AUTOSAR XML (schema 4-0-3)
standard types defined: UInt32, UInt8
package /AUTOSAR_Platform/DataConstrs
  range DC_UInt8: raw 0..255
package /PATAC/Facility/DataTypes/Implementation
  unit NoUnit: factor-si-to-unit=1, offset-si-to-unit=0
package /PATAC/MSM/ComponentTypes
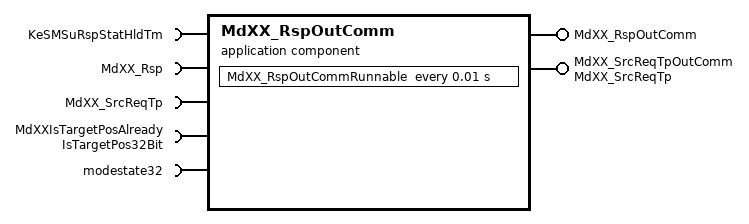
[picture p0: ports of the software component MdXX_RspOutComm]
  application sw component type MdXX_RspOutComm
    provide port MdXX_RspOutComm: provided-interface=MdXX_RspOutComm
      provided-com-specs:
        data-element=Md1_RspOutComm, init-value=0
        data-element=Md{10..19}_RspOutComm, init-value=0
        data-element=Md2_RspOutComm, init-value=0
        data-element=Md{20..29}_RspOutComm, init-value=0
        data-element=Md3_RspOutComm, init-value=0
        data-element=Md{30..32}_RspOutComm, init-value=0
        data-element=Md{4..9}_RspOutComm, init-value=0
    provide port MdXX_SrcReqTpOutComm: provided-interface=MdXX_SrcReqTp
      provided-com-specs:
        data-element=Md1_SrcTp, init-value=0
        data-element=Md{10..19}_SrcTp, init-value=0
        data-element=Md2_SrcTp, init-value=0
        data-element=Md{20..29}_SrcTp, init-value=0
        data-element=Md3_SrcTp, init-value=0
        data-element=Md{30..32}_SrcTp, init-value=0
        data-element=Md{4..9}_SrcTp, init-value=0
    5 x require port:
      KeSMSuRspStatHldTm: parameter-require-com-spec{init-value=100, parameter=Val}, required-interface=KeSMSuRspStatHldTm
      MdXX_Rsp: required-interface=MdXX_Rsp
        required-com-specs:
          data-element=Md1_Rsp, filter=data-filter-type=ALWAYS, init-value=0
          data-element=Md{10..19}_Rsp, filter=data-filter-type=ALWAYS, init-value=0
          data-element=Md2_Rsp, filter=data-filter-type=ALWAYS, init-value=0
          data-element=Md{20..29}_Rsp, filter=data-filter-type=ALWAYS, init-value=0
          data-element=Md3_Rsp, filter=data-filter-type=ALWAYS, init-value=0
          data-element=Md{30..32}_Rsp, filter=data-filter-type=ALWAYS, init-value=0
          data-element=Md{4..9}_Rsp, filter=data-filter-type=ALWAYS, init-value=0
      MdXX_SrcReqTp: required-interface=MdXX_SrcReqTp
        required-com-specs:
          data-element=Md1_SrcTp, filter=data-filter-type=ALWAYS, init-value=0
          data-element=Md{10..19}_SrcTp, filter=data-filter-type=ALWAYS, init-value=0
          data-element=Md2_SrcTp, filter=data-filter-type=ALWAYS, init-value=0
          data-element=Md{20..29}_SrcTp, filter=data-filter-type=ALWAYS, init-value=0
          data-element=Md3_SrcTp, filter=data-filter-type=ALWAYS, init-value=0
          data-element=Md{30..32}_SrcTp, filter=data-filter-type=ALWAYS, init-value=0
          data-element=Md{4..9}_SrcTp, filter=data-filter-type=ALWAYS, init-value=0
      MdXXIsTargetPosAlready: nonqueued-receiver-com-spec{data-element=IsTargetPos32Bit/Val, filter=data-filter-type=ALWAYS, init-value=0}, required-interface=IsTargetPos32Bit
      modestate32: nonqueued-receiver-com-spec{data-element=modestate32/Val, filter=data-filter-type=ALWAYS}, required-interface=modestate32
    behavior MdXX_RspOutComm_InternalBehavior
      timing event TMT_Runnable: start-on-event=MdXX_RspOutCommRunnable, period=0.01
      runnable MdXX_RspOutCommRunnable
        data-receive-point-by-arguments:
          66 x access:
            REC_IsTargetPos32Bit_Val: accessed-variable=MdXXIsTargetPosAlready.Val
            REC_MdXX_Rsp_Md1_Rsp: accessed-variable=MdXX_Rsp.Md1_Rsp
            REC_MdXX_Rsp_Md{10..19}_Rsp: accessed-variable=MdXX_Rsp.Md{10..19}_Rsp
            REC_MdXX_Rsp_Md2_Rsp: accessed-variable=MdXX_Rsp.Md2_Rsp
            REC_MdXX_Rsp_Md{20..29}_Rsp: accessed-variable=MdXX_Rsp.Md{20..29}_Rsp
            REC_MdXX_Rsp_Md3_Rsp: accessed-variable=MdXX_Rsp.Md3_Rsp
            REC_MdXX_Rsp_Md{30..32}_Rsp: accessed-variable=MdXX_Rsp.Md{30..32}_Rsp
            REC_MdXX_Rsp_Md{4..9}_Rsp: accessed-variable=MdXX_Rsp.Md{4..9}_Rsp
            REC_MdXX_SrcReqTp_Md1_SrcTp: accessed-variable=MdXX_SrcReqTp.Md1_SrcTp
            REC_MdXX_SrcReqTp_Md{10..19}_SrcTp: accessed-variable=MdXX_SrcReqTp.Md{10..19}_SrcTp
            REC_MdXX_SrcReqTp_Md2_SrcTp: accessed-variable=MdXX_SrcReqTp.Md2_SrcTp
            REC_MdXX_SrcReqTp_Md{20..29}_SrcTp: accessed-variable=MdXX_SrcReqTp.Md{20..29}_SrcTp
            REC_MdXX_SrcReqTp_Md3_SrcTp: accessed-variable=MdXX_SrcReqTp.Md3_SrcTp
            REC_MdXX_SrcReqTp_Md{30..32}_SrcTp: accessed-variable=MdXX_SrcReqTp.Md{30..32}_SrcTp
            REC_MdXX_SrcReqTp_Md{4..9}_SrcTp: accessed-variable=MdXX_SrcReqTp.Md{4..9}_SrcTp
            REC_modestate32_Val: accessed-variable=modestate32.Val
        data-send-points:
          64 x access:
            SEND_MdXX_RspOutComm_Md1_RspOutComm: accessed-variable=MdXX_RspOutComm.Md1_RspOutComm
            SEND_MdXX_RspOutComm_Md{10..19}_RspOutComm: accessed-variable=MdXX_RspOutComm.Md{10..19}_RspOutComm
            SEND_MdXX_RspOutComm_Md2_RspOutComm: accessed-variable=MdXX_RspOutComm.Md2_RspOutComm
            SEND_MdXX_RspOutComm_Md{20..29}_RspOutComm: accessed-variable=MdXX_RspOutComm.Md{20..29}_RspOutComm
            SEND_MdXX_RspOutComm_Md3_RspOutComm: accessed-variable=MdXX_RspOutComm.Md3_RspOutComm
            SEND_MdXX_RspOutComm_Md{30..32}_RspOutComm: accessed-variable=MdXX_RspOutComm.Md{30..32}_RspOutComm
            SEND_MdXX_RspOutComm_Md{4..9}_RspOutComm: accessed-variable=MdXX_RspOutComm.Md{4..9}_RspOutComm
            SEND_MdXX_SrcReqTpOutComm_Md1_SrcTp: accessed-variable=MdXX_SrcReqTpOutComm.Md1_SrcTp
            SEND_MdXX_SrcReqTpOutComm_Md{10..19}_SrcTp: accessed-variable=MdXX_SrcReqTpOutComm.Md{10..19}_SrcTp
            SEND_MdXX_SrcReqTpOutComm_Md2_SrcTp: accessed-variable=MdXX_SrcReqTpOutComm.Md2_SrcTp
            SEND_MdXX_SrcReqTpOutComm_Md{20..29}_SrcTp: accessed-variable=MdXX_SrcReqTpOutComm.Md{20..29}_SrcTp
            SEND_MdXX_SrcReqTpOutComm_Md3_SrcTp: accessed-variable=MdXX_SrcReqTpOutComm.Md3_SrcTp
            SEND_MdXX_SrcReqTpOutComm_Md{30..32}_SrcTp: accessed-variable=MdXX_SrcReqTpOutComm.Md{30..32}_SrcTp
            SEND_MdXX_SrcReqTpOutComm_Md{4..9}_SrcTp: accessed-variable=MdXX_SrcReqTpOutComm.Md{4..9}_SrcTp
        parameter access PA_KeSMSuRspStatHldTm_Val: accessed-parameter=KeSMSuRspStatHldTm.Val
  swc implementation MdXX_RspOutComm_Implementation: behavior=MdXX_RspOutComm_InternalBehavior
    code-descriptors:
      code Default: artifact-descriptors=autosar-engineering-object={short-label=Default, category=SWSRC}
package /PATAC/MSM/ModeAdjust/CalPortInterface
  parameter interface KeSMSuRspStatHldTm
    parameter data prototype Val: sw-calibration-access=READ-WRITE, type=UInt8
package /PATAC/MSM/ModeAdjust/DataType
  impl type MdRspLocal2: category=VALUE, base-type=UInt8, sw-calibration-access=READ-ONLY, compu {0=MdRsp_None, 1=MdRsp_RecallSuccessfully, 2=MdRsp_RecallUnsuccessfully_LocalInterrupt, 3=MdRsp_RecallUnsuccessfully_NonEnghSpace, 4=MdRsp_RecallOngoing, 5=MdRsp_TargetPositionAlready, 6=MdRsp_LowPower, 7=MdRsp_CrashStat, 8=MdRsp_ThdRwOccupt, 9=MdRsp_PosNotLrn, 10=MdRsp_NotParkStat, 11=MdRsp_SpdNotCorrt}, type-emitter=RTE
  impl type SrcReqTp1: category=VALUE, base-type=UInt8, sw-calibration-access=READ-ONLY, compu {0=SrcReqTp_None, 1=SrcReqTp_Local, 2=SrcReqTp_HMI2L, 3=SrcReqTp_HMI2R, 4=SrcReqTp_HMI, 5=SrcReqTp_Remote, 6=SrcReqTp_SRS}, type-emitter=RTE
package /PATAC/MSM/ModeAdjust/PortInterface
  5 x sender receiver interface:
    IsTargetPos32Bit: invalidation-policy{data-element=IsTargetPos32Bit/Val, handle-invalid=DONT-INVALIDATE}
      data Val: type=UInt32
    MdXX_Rsp
      32 x data, all with type=MdRspLocal2:
        Md1_Rsp
        Md{10..19}_Rsp
        Md2_Rsp
        Md{20..29}_Rsp
        Md3_Rsp
        Md{30..32}_Rsp
        Md{4..9}_Rsp
      invalidation-policys:
        data-element=Md1_Rsp, handle-invalid=DONT-INVALIDATE
        data-element=Md2_Rsp, handle-invalid=DONT-INVALIDATE
        data-element=Md5_Rsp, handle-invalid=DONT-INVALIDATE
        data-element=Md3_Rsp, handle-invalid=DONT-INVALIDATE
        data-element=Md7_Rsp, handle-invalid=DONT-INVALIDATE
        data-element=Md4_Rsp, handle-invalid=DONT-INVALIDATE
        data-element=Md6_Rsp, handle-invalid=DONT-INVALIDATE
        data-element=Md9_Rsp, handle-invalid=DONT-INVALIDATE
        data-element=Md8_Rsp, handle-invalid=DONT-INVALIDATE
        data-element=Md11_Rsp, handle-invalid=DONT-INVALIDATE
        data-element=Md10_Rsp, handle-invalid=DONT-INVALIDATE
        data-element=Md13_Rsp, handle-invalid=DONT-INVALIDATE
        data-element=Md12_Rsp, handle-invalid=DONT-INVALIDATE
        data-element=Md21_Rsp, handle-invalid=DONT-INVALIDATE
        data-element=Md14_Rsp, handle-invalid=DONT-INVALIDATE
        data-element=Md20_Rsp, handle-invalid=DONT-INVALIDATE
        data-element=Md15_Rsp, handle-invalid=DONT-INVALIDATE
        data-element=Md19_Rsp, handle-invalid=DONT-INVALIDATE
        data-element=Md16_Rsp, handle-invalid=DONT-INVALIDATE
        data-element=Md23_Rsp, handle-invalid=DONT-INVALIDATE
        data-element=Md17_Rsp, handle-invalid=DONT-INVALIDATE
        data-element=Md22_Rsp, handle-invalid=DONT-INVALIDATE
        data-element=Md18_Rsp, handle-invalid=DONT-INVALIDATE
        data-element=Md28_Rsp, handle-invalid=DONT-INVALIDATE
        data-element=Md24_Rsp, handle-invalid=DONT-INVALIDATE
        data-element=Md30_Rsp, handle-invalid=DONT-INVALIDATE
        data-element=Md25_Rsp, handle-invalid=DONT-INVALIDATE
        data-element=Md29_Rsp, handle-invalid=DONT-INVALIDATE
        data-element=Md26_Rsp, handle-invalid=DONT-INVALIDATE
        data-element=Md31_Rsp, handle-invalid=DONT-INVALIDATE
        data-element=Md32_Rsp, handle-invalid=DONT-INVALIDATE
        data-element=Md27_Rsp, handle-invalid=DONT-INVALIDATE
    MdXX_RspOutComm
      32 x data, all with type=UInt8:
        Md1_RspOutComm
        Md{10..19}_RspOutComm
        Md2_RspOutComm
        Md{20..29}_RspOutComm
        Md3_RspOutComm
        Md{30..32}_RspOutComm
        Md{4..9}_RspOutComm
      invalidation-policys:
        data-element=Md1_RspOutComm, handle-invalid=DONT-INVALIDATE
        data-element=Md11_RspOutComm, handle-invalid=DONT-INVALIDATE
        data-element=Md12_RspOutComm, handle-invalid=DONT-INVALIDATE
        data-element=Md14_RspOutComm, handle-invalid=DONT-INVALIDATE
        data-element=Md13_RspOutComm, handle-invalid=DONT-INVALIDATE
        data-element=Md19_RspOutComm, handle-invalid=DONT-INVALIDATE
        data-element=Md15_RspOutComm, handle-invalid=DONT-INVALIDATE
        data-element=Md18_RspOutComm, handle-invalid=DONT-INVALIDATE
        data-element=Md16_RspOutComm, handle-invalid=DONT-INVALIDATE
        data-element=Md17_RspOutComm, handle-invalid=DONT-INVALIDATE
        data-element=Md2_RspOutComm, handle-invalid=DONT-INVALIDATE
        data-element=Md21_RspOutComm, handle-invalid=DONT-INVALIDATE
        data-element=Md22_RspOutComm, handle-invalid=DONT-INVALIDATE
        data-element=Md24_RspOutComm, handle-invalid=DONT-INVALIDATE
        data-element=Md23_RspOutComm, handle-invalid=DONT-INVALIDATE
        data-element=Md{25..27}_RspOutComm, handle-invalid=DONT-INVALIDATE
        data-element=Md29_RspOutComm, handle-invalid=DONT-INVALIDATE
        data-element=Md28_RspOutComm, handle-invalid=DONT-INVALIDATE
        data-element=Md3_RspOutComm, handle-invalid=DONT-INVALIDATE
        data-element=Md31_RspOutComm, handle-invalid=DONT-INVALIDATE
        data-element=Md32_RspOutComm, handle-invalid=DONT-INVALIDATE
        data-element=Md{4..6}_RspOutComm, handle-invalid=DONT-INVALIDATE
        data-element=Md9_RspOutComm, handle-invalid=DONT-INVALIDATE
        data-element=Md7_RspOutComm, handle-invalid=DONT-INVALIDATE
        data-element=Md8_RspOutComm, handle-invalid=DONT-INVALIDATE
        data-element=Md10_RspOutComm, handle-invalid=DONT-INVALIDATE
        data-element=Md20_RspOutComm, handle-invalid=DONT-INVALIDATE
        data-element=Md30_RspOutComm, handle-invalid=DONT-INVALIDATE
    MdXX_SrcReqTp
      32 x data, all with type=SrcReqTp1:
        Md1_SrcTp
        Md{10..19}_SrcTp
        Md2_SrcTp
        Md{20..29}_SrcTp
        Md3_SrcTp
        Md{30..32}_SrcTp
        Md{4..9}_SrcTp
      invalidation-policys:
        data-element=Md1_SrcTp, handle-invalid=DONT-INVALIDATE
        data-element=Md2_SrcTp, handle-invalid=DONT-INVALIDATE
        data-element=Md4_SrcTp, handle-invalid=DONT-INVALIDATE
        data-element=Md3_SrcTp, handle-invalid=DONT-INVALIDATE
        data-element=Md6_SrcTp, handle-invalid=DONT-INVALIDATE
        data-element=Md5_SrcTp, handle-invalid=DONT-INVALIDATE
        data-element=Md10_SrcTp, handle-invalid=DONT-INVALIDATE
        data-element=Md7_SrcTp, handle-invalid=DONT-INVALIDATE
        data-element=Md12_SrcTp, handle-invalid=DONT-INVALIDATE
        data-element=Md8_SrcTp, handle-invalid=DONT-INVALIDATE
        data-element=Md11_SrcTp, handle-invalid=DONT-INVALIDATE
        data-element=Md9_SrcTp, handle-invalid=DONT-INVALIDATE
        data-element=Md14_SrcTp, handle-invalid=DONT-INVALIDATE
        data-element=Md13_SrcTp, handle-invalid=DONT-INVALIDATE
        data-element=Md17_SrcTp, handle-invalid=DONT-INVALIDATE
        data-element=Md16_SrcTp, handle-invalid=DONT-INVALIDATE
        data-element=Md15_SrcTp, handle-invalid=DONT-INVALIDATE
        data-element=Md19_SrcTp, handle-invalid=DONT-INVALIDATE
        data-element=Md18_SrcTp, handle-invalid=DONT-INVALIDATE
        data-element=Md{20..22}_SrcTp, handle-invalid=DONT-INVALIDATE
        data-element=Md24_SrcTp, handle-invalid=DONT-INVALIDATE
        data-element=Md23_SrcTp, handle-invalid=DONT-INVALIDATE
        data-element=Md26_SrcTp, handle-invalid=DONT-INVALIDATE
        data-element=Md25_SrcTp, handle-invalid=DONT-INVALIDATE
        data-element=Md28_SrcTp, handle-invalid=DONT-INVALIDATE
        data-element=Md27_SrcTp, handle-invalid=DONT-INVALIDATE
        data-element=Md30_SrcTp, handle-invalid=DONT-INVALIDATE
        data-element=Md29_SrcTp, handle-invalid=DONT-INVALIDATE
        data-element=Md32_SrcTp, handle-invalid=DONT-INVALIDATE
        data-element=Md31_SrcTp, handle-invalid=DONT-INVALIDATE
    modestate32: invalidation-policy{data-element=modestate32/Val, handle-invalid=DONT-INVALIDATE}
      data Val: type=UInt32
